# STM32N645xx register map
File version: 1.0
Registers are 32-bit, read-write, reset 0x0 unless marked. A register's access mark holds for its fields unless they carry their own. Offsets are from the block's base; [hi:lo] are bit positions; {n}, {i} and the like mark numbered series.

## SDMMC2 — Secure digital input/output Interface
Base 0x48026800
Same registers: SDMMC1 0x48027000
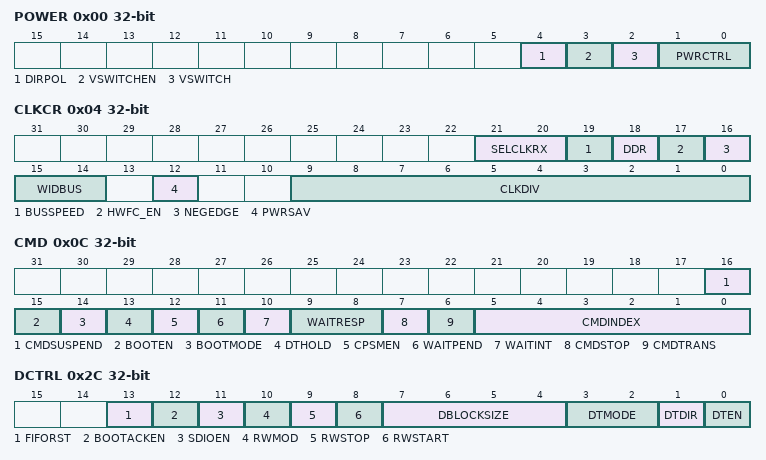
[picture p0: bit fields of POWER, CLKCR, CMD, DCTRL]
0x00 POWER — SDMMC power control register
  [4] DIRPOL — Data and Command direction signals polarity selection
  [3] VSWITCHEN — Voltage switch procedure enable
  [2] VSWITCH — Voltage switch sequence start
  [1:0] PWRCTRL — PWRCTRL[1:0] bits (Power supply control bits)
0x04 CLKCR — SDMMC clock control register
  [21:20] SELCLKRX — SELCLKRX[1:0] bits (Receive clock selection)
  [19] BUSSPEED — Bus speed mode selection
  [18] DDR — Data rate signaling selection
  [17] HWFC_EN — HW Flow Control enable
  [16] NEGEDGE — SDMMC_CK dephasing selection bit
  [15:14] WIDBUS — WIDBUS[1:0] bits (Wide bus mode enable bit)
  [12] PWRSAV — Power saving configuration bit
  [9:0] CLKDIV — Clock divide factor
0x08 ARG — SDMMC argument register
  [31:0] CMDARG — Command argument
0x0C CMD — SDMMC command register
  [16] CMDSUSPEND — CPSM Treats command as a Suspend or Resume command
  [15] BOOTEN — Enable Boot mode procedure
  [14] BOOTMODE
  [13] DTHOLD — Hold new data block transmission and reception in the DPSM
  [12] CPSMEN — Command path state machine (CPSM) Enable bit
  [11] WAITPEND — CPSM Waits for ends of data transfer (CmdPend internal signal)
  [10] WAITINT — CPSM Waits for Interrupt Request
  [9:8] WAITRESP — WAITRESP[1:0] bits (Wait for response bits)
  [7] CMDSTOP — CPSM Treats command as a Stop
  [6] CMDTRANS — CPSM Treats command as a Data Transfer
  [5:0] CMDINDEX — Command Index
0x10 RESPCMD ro — SDMMC command response register
  [5:0] RESPCMD — Response command index
{0x10+4i} RESP{i} ro (i=1..4) — SDMMC response {i} register
  [31:0] CARDSTATUS{i} — Card Status
0x24 DTIMER — SDMMC data timer register
  [31:0] DATATIME — Data timeout period
0x28 DLEN — SDMMC data length register
  [24:0] DATALENGTH — Data length value
0x2C DCTRL — SDMMC data control register
  [13] FIFORST — FIFO reset
  [12] BOOTACKEN — Enable the reception of the Boot Acknowledgment
  [11] SDIOEN — SD I/O enable functions
  [10] RWMOD — Read wait mode
  [9] RWSTOP — Read wait stop
  [8] RWSTART — Read wait start
  [7:4] DBLOCKSIZE — DBLOCKSIZE[3:0] bits (Data block size)
  [3:2] DTMODE — DTMODE[1:0] Data transfer mode selection
  [1] DTDIR — Data transfer direction selection
  [0] DTEN — Data transfer enabled bit
0x30 DCOUNT ro — SDMMC data counter register
  [24:0] DATACOUNT — Data count value
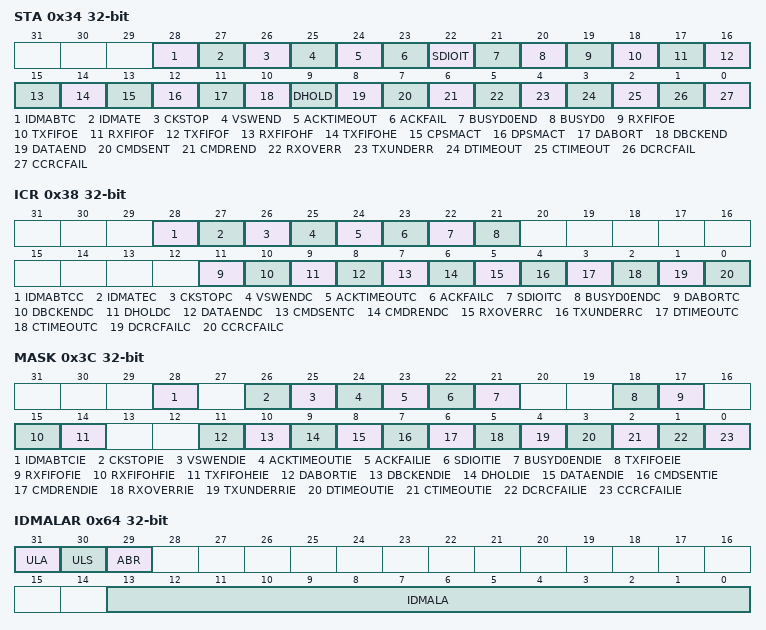
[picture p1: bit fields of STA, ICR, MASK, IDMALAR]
0x34 STA ro — SDMMC status register
  [28] IDMABTC — IDMA buffer transfer complete
  [27] IDMATE — IDMA transfer error
  [26] CKSTOP — SDMMC_CK stopped in Voltage switch procedure
  [25] VSWEND — Voltage switch critical timing section completion
  [24] ACKTIMEOUT — Boot Acknowledgment timeout
  [23] ACKFAIL — Boot Acknowledgment received (BootAck check fail)
  [22] SDIOIT — SDIO interrupt received
  [21] BUSYD0END — End of SDMMC_D0 Busy following a CMD response detected
  [20] BUSYD0 — Inverted value of SDMMC_D0 line (Busy)
  [19] RXFIFOE — Receive FIFO empty
  [18] TXFIFOE — Transmit FIFO empty
  [17] RXFIFOF — Receive FIFO full
  [16] TXFIFOF — Transmit FIFO full
  [15] RXFIFOHF — Receive FIFO Half Full: there are at least 8 words in the FIFO
  [14] TXFIFOHE — Transmit FIFO Half Empty: at least 8 words can be written into the FIFO
  [13] CPSMACT — Command path state machine active
  [12] DPSMACT — Data path state machine active
  [11] DABORT — Data transfer aborted by CMD12
  [10] DBCKEND — Data block sent/received (CRC check passed)
  [9] DHOLD — Data transfer Hold
  [8] DATAEND — Data end (data counter, SDIDCOUNT, is zero)
  [7] CMDSENT — Command sent (no response required)
  [6] CMDREND — Command response received (CRC check passed)
  [5] RXOVERR — Received FIFO overrun error
  [4] TXUNDERR — Transmit FIFO underrun error
  [3] DTIMEOUT — Data timeout
  [2] CTIMEOUT — Command response timeout
  [1] DCRCFAIL — Data block sent/received (CRC check failed)
  [0] CCRCFAIL — Command response received (CRC check failed)
0x38 ICR — SDMMC interrupt clear register
  [28] IDMABTCC — IDMABTCC flag clear bit
  [27] IDMATEC — IDMATEC flag clear bit
  [26] CKSTOPC — CKSTOPC flag clear bit
  [25] VSWENDC — VSWENDC flag clear bit
  [24] ACKTIMEOUTC — ACKTIMEOUTC flag clear bit
  [23] ACKFAILC — ACKFAILC flag clear bit
  [22] SDIOITC — SDIOIT flag clear bit
  [21] BUSYD0ENDC — BUSYD0ENDC flag clear bit
  [11] DABORTC — DABORTC flag clear bit
  [10] DBCKENDC — DBCKEND flag clear bit
  [9] DHOLDC — DHOLD flag clear bit
  [8] DATAENDC — DATAEND flag clear bit
  [7] CMDSENTC — CMDSENT flag clear bit
  [6] CMDRENDC — CMDREND flag clear bit
  [5] RXOVERRC — RXOVERR flag clear bit
  [4] TXUNDERRC — TXUNDERR flag clear bit
  [3] DTIMEOUTC — DTIMEOUT flag clear bit
  [2] CTIMEOUTC — CTIMEOUT flag clear bit
  [1] DCRCFAILC — DCRCFAIL flag clear bit
  [0] CCRCFAILC — CCRCFAIL flag clear bit
0x3C MASK — SDMMC mask register
  [28] IDMABTCIE — IDMA buffer transfer complete Interrupt Enable
  [26] CKSTOPIE — Voltage Switch clock stopped Interrupt Enable
  [25] VSWENDIE — Voltage switch critical timing section completion Interrupt Enable
  [24] ACKTIMEOUTIE — Acknowledgment timeout Interrupt Enable
  [23] ACKFAILIE — Acknowledgment Fail Interrupt Enable
  [22] SDIOITIE — SDMMC Mode Interrupt Received interrupt Enable
  [21] BUSYD0ENDIE — BUSYD0ENDIE interrupt Enable
  [18] TXFIFOEIE — Tx FIFO Empty interrupt Enable
  [17] RXFIFOFIE — Rx FIFO Full interrupt Enable
  [15] RXFIFOHFIE — Rx FIFO Half Full interrupt Enable
  [14] TXFIFOHEIE — Tx FIFO Half Empty interrupt Enable
  [11] DABORTIE — Data transfer aborted interrupt enable
  [10] DBCKENDIE — Data Block End Interrupt Enable
  [9] DHOLDIE — Data Hold Interrupt Enable
  [8] DATAENDIE — Data End Interrupt Enable
  [7] CMDSENTIE — Command Sent Interrupt Enable
  [6] CMDRENDIE — Command Response Received Interrupt Enable
  [5] RXOVERRIE — Rx FIFO OverRun Error Interrupt Enable
  [4] TXUNDERRIE — Tx FIFO UnderRun Error Interrupt Enable
  [3] DTIMEOUTIE — Data TimeOut Interrupt Enable
  [2] CTIMEOUTIE — Command TimeOut Interrupt Enable
  [1] DCRCFAILIE — Data CRC Fail Interrupt Enable
  [0] CCRCFAILIE — Command CRC Fail Interrupt Enable
0x40 ACKTIME — SDMMC Acknowledgement timer register
  [24:0] ACKTIME — Boot acknowledgment timeout period
0x44 FIFOTHR — SDMMC data FIFO threshold register
  [3:0] THR — FIFO threshold
0x50 IDMACTRL — SDMMC DMA control register
0x54 IDMABSIZE — SDMMC DMA buffer size register
  [16:6] IDMABNDT — Number of transfers per buffer
0x58 IDMABASER — SDMMC DMA buffer base address register
0x64 IDMALAR — SDMMC DMA linked list address register
  [31] ULA — Update Address from linked list
  [30] ULS — Update Size from linked list
  [29] ABR — Acknowledge linked list buffer ready
  [13:0] IDMALA — Linked list item address offset
0x68 IDMABAR — SDMMC DMA linked list memory base register
0x80 FIFO — SDMMC data FIFO register
  [31:0] FIFODATA — Receive and transmit FIFO data
